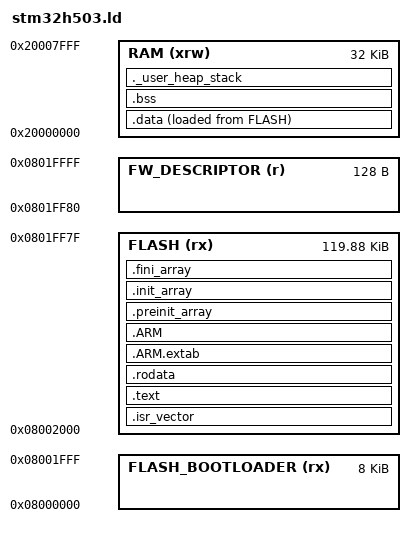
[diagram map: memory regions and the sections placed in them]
/*
******************************************************************************
**
** @file        : LinkerScript.ld
**
** @author      : Auto-generated by STM32CubeIDE
**
** @brief       : Linker script for STM32H503RBTx Device from STM32H5 series
**                      128Kbytes FLASH
**                      32Kbytes RAM
**
**                Set heap size, stack size and stack location according
**                to application requirements.
**
**                Set memory bank area and size if external memory is used
**
**  Target      : STMicroelectronics STM32
**
**  Distribution: The file is distributed as is, without any warranty
**                of any kind.
**
******************************************************************************
** @attention
**
** Copyright (c) 2023 STMicroelectronics.
** All rights reserved.
**
** This software is licensed under terms that can be found in the LICENSE file
** in the root directory of this software component.
** If no LICENSE file comes with this software, it is provided AS-IS.
**
******************************************************************************
*/

/* Entry Point */
ENTRY(Reset_Handler)

/* Highest address of the user mode stack */
_estack = ORIGIN(RAM) + LENGTH(RAM); /* end of "RAM" Ram type memory */

_Min_Heap_Size = 0x200; /* required amount of heap */
_Min_Stack_Size = 0x400; /* required amount of stack */

TOTAL_FLASH_SIZE = 128K;
FLASH_ONE_PAGE = 8K;
FW_ORIGIN = 0x8000000;

BL_SIZE = 8K;
DESCRIPTOR_SIZE = 128;
APP_SIZE = TOTAL_FLASH_SIZE - BL_SIZE - DESCRIPTOR_SIZE;

/* Memories definition */
MEMORY
{
  RAM    (xrw)    : ORIGIN = 0x20000000,   LENGTH = 32K
  FLASH_BOOTLOADER (rx) : ORIGIN = FW_ORIGIN, LENGTH = BL_SIZE
  FLASH    (rx)    : ORIGIN = FW_ORIGIN + BL_SIZE,   LENGTH = APP_SIZE
  FW_DESCRIPTOR (r) : ORIGIN = FW_ORIGIN + TOTAL_FLASH_SIZE - DESCRIPTOR_SIZE, LENGTH = DESCRIPTOR_SIZE
}

/* Sections */
SECTIONS
{
  /* The startup code into "FLASH" Rom type memory */
  .isr_vector :
  {
    . = ALIGN(4);
    KEEP(*(.isr_vector)) /* Startup code */
    . = ALIGN(4);
  } >FLASH

  /* The program code and other data into "FLASH" Rom type memory */
  .text :
  {
    . = ALIGN(32);
    __privileged_functions_start__ = .;
    *(privileged_functions)
    . = ALIGN(32);
    __privileged_functions_end__ = . - 1;
    __syscalls_flash_start__ = .;
    *(freertos_system_calls)
    . = ALIGN(32);
    __syscalls_flash_end__ = . - 1;
    __unprivileged_flash_start__ = .;
    *(.text)           /* .text sections (code) */
    *(.text*)          /* .text* sections (code) */
    *(.glue_7)         /* glue arm to thumb code */
    *(.glue_7t)        /* glue thumb to arm code */
    *(.eh_frame)

    KEEP (*(.init))
    KEEP (*(.fini))

    . = ALIGN(4);
    _etext = .;        /* define a global symbols at end of code */
  } >FLASH

  /* Constant data into "FLASH" Rom type memory */
  .rodata :
  {
    . = ALIGN(4);
    *(.rodata)         /* .rodata sections (constants, strings, etc.) */
    *(.rodata*)        /* .rodata* sections (constants, strings, etc.) */
    . = ALIGN(4);
  } >FLASH

  .ARM.extab (READONLY) : /* The READONLY keyword is only supported in GCC11 and later, remove it if using GCC10 or earlier. */
  {
    . = ALIGN(4);
    *(.ARM.extab* .gnu.linkonce.armextab.*)
    . = ALIGN(4);
  } >FLASH

  .ARM (READONLY) : /* The READONLY keyword is only supported in GCC11 and later, remove it if using GCC10 or earlier. */
  {
    . = ALIGN(4);
    __exidx_start = .;
    *(.ARM.exidx*)
    __exidx_end = .;
    . = ALIGN(4);
  } >FLASH

  .preinit_array (READONLY) : /* The READONLY keyword is only supported in GCC11 and later, remove it if using GCC10 or earlier. */
  {
    . = ALIGN(4);
    PROVIDE_HIDDEN (__preinit_array_start = .);
    KEEP (*(.preinit_array*))
    PROVIDE_HIDDEN (__preinit_array_end = .);
    . = ALIGN(4);
  } >FLASH

  .init_array (READONLY) : /* The READONLY keyword is only supported in GCC11 and later, remove it if using GCC10 or earlier. */
  {
    . = ALIGN(4);
    PROVIDE_HIDDEN (__init_array_start = .);
    KEEP (*(SORT(.init_array.*)))
    KEEP (*(.init_array*))
    PROVIDE_HIDDEN (__init_array_end = .);
    . = ALIGN(4);
  } >FLASH

  .fini_array (READONLY) : /* The READONLY keyword is only supported in GCC11 and later, remove it if using GCC10 or earlier. */
  {
    . = ALIGN(4);
    PROVIDE_HIDDEN (__fini_array_start = .);
    KEEP (*(SORT(.fini_array.*)))
    KEEP (*(.fini_array*))
    PROVIDE_HIDDEN (__fini_array_end = .);
    . = ALIGN(32);
    __unprivileged_flash_end__ = . - 1;
  } >FLASH

  /* Used by the startup to initialize data */
  _sidata = LOADADDR(.data);

  /* Initialized data sections into "RAM" Ram type memory */
  .data :
  {
    . = ALIGN(32);
    _sdata = .;        /* create a global symbol at data start */
    __privileged_sram_start__ = .;
    *(privileged_data);
    . = ALIGN(32);
    __privileged_sram_end__ = . - 1;
    __non_shared_data_start__ = .;
    *(non_shared_data);
    . = ALIGN(32);
    __non_shared_data_end = . - 1;
    __shared_data_start__ = .;
    *(.data)           /* .data sections */
    *(.data*)          /* .data* sections */
    *(.RamFunc)        /* .RamFunc sections */
    *(.RamFunc*)       /* .RamFunc* sections */
    _edata = .;        /* define a global symbol at data end */
  } >RAM AT> FLASH

  /* Uninitialized data section into "RAM" Ram type memory */
  . = ALIGN(4);
  .bss :
  {
    /* This is used by the startup in order to initialize the .bss section */
    _sbss = .;         /* define a global symbol at bss start */
    __bss_start__ = _sbss;
    *(.bss)
    *(.bss*)
    *(COMMON)

    . = ALIGN(32);
    __shared_data_end__ = . - 1;
    _ebss = .;         /* define a global symbol at bss end */
    __bss_end__ = _ebss;
  } >RAM

  /* User_heap_stack section, used to check that there is enough "RAM" Ram  type memory left */
  ._user_heap_stack :
  {
    . = ALIGN(8);
    PROVIDE ( end = . );
    PROVIDE ( _end = . );
    . = . + _Min_Heap_Size;
    . = . + _Min_Stack_Size;
    . = ALIGN(8);
  } >RAM

/* Remove information from the standard libraries */
  /DISCARD/ :
  {
    libc.a:* ( * )
    libc_nano* ( * )
    libm.a:* ( * )
    libgcc.a:* ( * )
    *(.ARM.exidx*)
    *(.ARM.extab* .gnu.linkonce.armextab.*)
  }

  .ARM.attributes 0 : { *(.ARM.attributes) }
}
